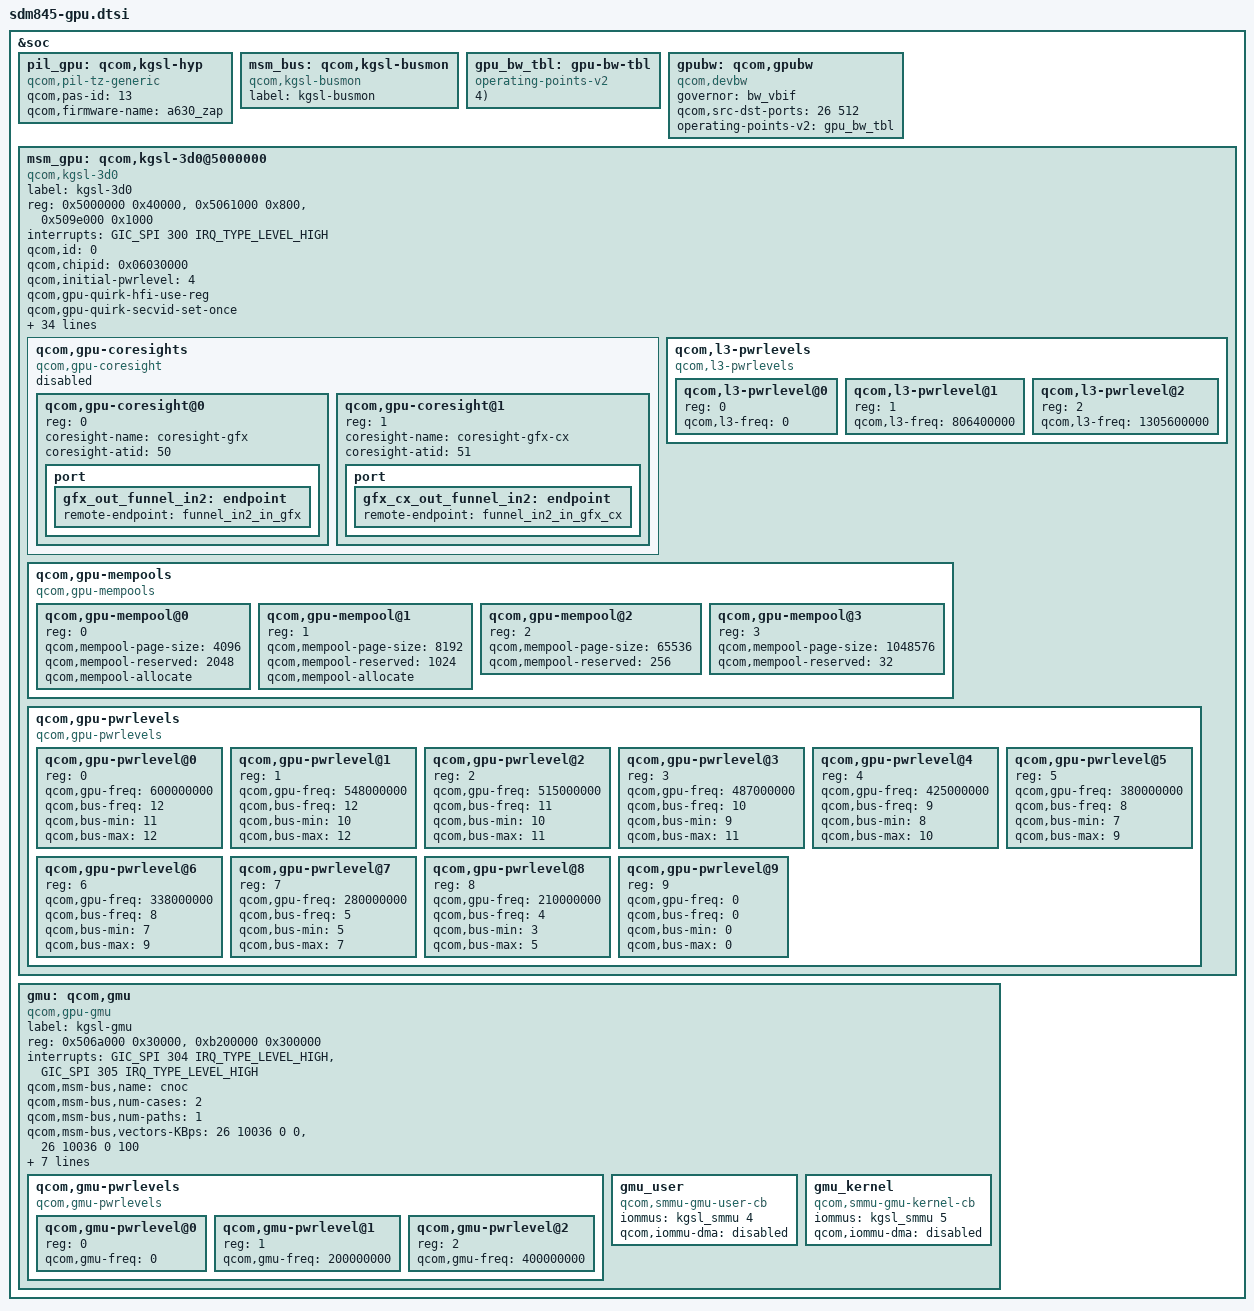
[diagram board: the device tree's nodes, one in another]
// SPDX-License-Identifier: GPL-2.0-only
/*
 * Copyright (c) 2017-2019, The Linux Foundation. All rights reserved.
 * GPU Optimized: Added intermediate freq levels, tuned defaults
 */

&soc {

	pil_gpu: qcom,kgsl-hyp {
		compatible = "qcom,pil-tz-generic";
		qcom,pas-id = <13>;
		qcom,firmware-name = "a630_zap";
	};

	msm_bus: qcom,kgsl-busmon{
		label = "kgsl-busmon";
		compatible = "qcom,kgsl-busmon";
	};

	gpu_bw_tbl: gpu-bw-tbl {
		compatible = "operating-points-v2";
		BW_OPP_ENTRY(   0, 4); /*    0 MB/s */
		BW_OPP_ENTRY( 100, 4); /*  381 MB/s */
		BW_OPP_ENTRY( 150, 4); /*  572 MB/s */
		BW_OPP_ENTRY( 200, 4); /*  762 MB/s */
		BW_OPP_ENTRY( 300, 4); /* 1144 MB/s */
		BW_OPP_ENTRY( 412, 4); /* 1571 MB/s */
		BW_OPP_ENTRY( 547, 4); /* 2086 MB/s */
		BW_OPP_ENTRY( 681, 4); /* 2597 MB/s */
		BW_OPP_ENTRY( 768, 4); /* 2929 MB/s */
		BW_OPP_ENTRY(1017, 4); /* 3879 MB/s */
		BW_OPP_ENTRY(1296, 4); /* 4943 MB/s */
		BW_OPP_ENTRY(1555, 4); /* 5931 MB/s */
		BW_OPP_ENTRY(1804, 4); /* 6881 MB/s */
	};

	gpubw: qcom,gpubw {
		compatible = "qcom,devbw";
		governor = "bw_vbif";
		qcom,src-dst-ports = <26 512>;
		operating-points-v2 = <&gpu_bw_tbl>;
	};

	msm_gpu: qcom,kgsl-3d0@5000000 {
		label = "kgsl-3d0";
		compatible = "qcom,kgsl-3d0", "qcom,kgsl-3d";
		status = "ok";
		reg = <0x5000000 0x40000>, <0x5061000 0x800>,
			<0x509e000 0x1000>;
		reg-names = "kgsl_3d0_reg_memory", "cx_dbgc",
			"cx_misc";
		interrupts = <GIC_SPI 300 IRQ_TYPE_LEVEL_HIGH>;
		interrupt-names = "kgsl_3d0_irq";
		qcom,id = <0>;

		qcom,chipid = <0x06030000>;

		qcom,initial-pwrlevel = <4>; /* Optimized: 338MHz (was 5=280MHz) */

		qcom,gpu-quirk-hfi-use-reg;
		qcom,gpu-quirk-secvid-set-once;

		qcom,idle-timeout = <60>; /* Optimized: 60ms (was 80ms) */
		qcom,no-nap;

		qcom,highest-bank-bit = <15>;

		qcom,min-access-length = <32>;

		qcom,ubwc-mode = <2>;

		qcom,snapshot-size = <1048576>;

		qcom,gpu-qdss-stm = <0x161c0000 0x40000>;

		qcom,tsens-name = "tsens_tz_sensor12";
		#cooling-cells = <2>;

		tzone-names = "gpu0-usr", "gpu1-usr";

		qcom,pm-qos-active-latency = <460>;

		clocks = <&clock_gfx GPU_CC_GX_GFX3D_CLK>,
			<&clock_gpucc GPU_CC_CXO_CLK>,
			<&clock_gcc GCC_DDRSS_GPU_AXI_CLK>,
			<&clock_gcc GCC_GPU_MEMNOC_GFX_CLK>,
			<&clock_gpucc GPU_CC_CX_GMU_CLK>,
			<&clock_cpucc L3_GPU_VOTE_CLK>;

		clock-names = "core_clk", "rbbmtimer_clk", "mem_clk",
				"mem_iface_clk", "gmu_clk", "l3_vote";

		qcom,isense-clk-on-level = <1>;

		qcom,gpubw-dev = <&gpubw>;
		qcom,bus-control;
		qcom,msm-bus,name = "grp3d";
		qcom,bus-width = <32>;
		qcom,msm-bus,num-cases = <13>;
		qcom,msm-bus,num-paths = <1>;
		qcom,msm-bus,vectors-KBps =
				<26 512 0 0>,
				<26 512 0 400000>,
				<26 512 0 600000>,
				<26 512 0 800000>,
				<26 512 0 1200000>,
				<26 512 0 1648000>,
				<26 512 0 2188000>,
				<26 512 0 2724000>,
				<26 512 0 3072000>,
				<26 512 0 4068000>,
				<26 512 0 5184000>,
				<26 512 0 6220000>,
				<26 512 0 7216000>;

		regulator-names = "vddcx", "vdd";
		vddcx-supply = <&gpu_cx_gdsc>;
		vdd-supply = <&gpu_gx_gdsc>;

		cache-slice-names = "gpu", "gpuhtw";

		qcom,gpu-coresights {
			#address-cells = <1>;
			#size-cells = <0>;
			compatible = "qcom,gpu-coresight";
			status = "disabled";
			qcom,gpu-coresight@0 {
				reg = <0>;
				coresight-name = "coresight-gfx";
				coresight-atid = <50>;
				port {
					gfx_out_funnel_in2: endpoint {
						remote-endpoint = <&funnel_in2_in_gfx>;
					};
				};
			};
			qcom,gpu-coresight@1 {
				reg = <1>;
				coresight-name = "coresight-gfx-cx";
				coresight-atid = <51>;
				port {
					gfx_cx_out_funnel_in2: endpoint {
						remote-endpoint = <&funnel_in2_in_gfx_cx>;
					};
				};
			};
		};

		qcom,l3-pwrlevels {
			#address-cells = <1>;
			#size-cells = <0>;
			compatible = "qcom,l3-pwrlevels";
			qcom,l3-pwrlevel@0 { reg = <0>; qcom,l3-freq = <0>; };
			qcom,l3-pwrlevel@1 { reg = <1>; qcom,l3-freq = <806400000>; };
			qcom,l3-pwrlevel@2 { reg = <2>; qcom,l3-freq = <1305600000>; };
		};

		qcom,gpu-mempools {
			#address-cells = <1>;
			#size-cells = <0>;
			compatible = "qcom,gpu-mempools";
			qcom,gpu-mempool@0 { reg = <0>; qcom,mempool-page-size = <4096>; qcom,mempool-reserved = <2048>; qcom,mempool-allocate; };
			qcom,gpu-mempool@1 { reg = <1>; qcom,mempool-page-size = <8192>; qcom,mempool-reserved = <1024>; qcom,mempool-allocate; };
			qcom,gpu-mempool@2 { reg = <2>; qcom,mempool-page-size = <65536>; qcom,mempool-reserved = <256>; };
			qcom,gpu-mempool@3 { reg = <3>; qcom,mempool-page-size = <1048576>; qcom,mempool-reserved = <32>; };
		};

		/* Optimized GPU Power Levels: 10 levels with intermediate freqs */
		qcom,gpu-pwrlevels {
			#address-cells = <1>;
			#size-cells = <0>;
			compatible = "qcom,gpu-pwrlevels";

			qcom,gpu-pwrlevel@0 {
				reg = <0>;
				qcom,gpu-freq = <600000000>;
				qcom,bus-freq = <12>;
				qcom,bus-min = <11>;
				qcom,bus-max = <12>;
			};

			qcom,gpu-pwrlevel@1 {
				reg = <1>;
				qcom,gpu-freq = <548000000>;
				qcom,bus-freq = <12>;
				qcom,bus-min = <10>;
				qcom,bus-max = <12>;
			};

			qcom,gpu-pwrlevel@2 {
				reg = <2>;
				qcom,gpu-freq = <515000000>; /* NEW: intermediate */
				qcom,bus-freq = <11>;
				qcom,bus-min = <10>;
				qcom,bus-max = <11>;
			};

			qcom,gpu-pwrlevel@3 {
				reg = <3>;
				qcom,gpu-freq = <487000000>;
				qcom,bus-freq = <10>;
				qcom,bus-min = <9>;
				qcom,bus-max = <11>;
			};

			qcom,gpu-pwrlevel@4 {
				reg = <4>;
				qcom,gpu-freq = <425000000>;
				qcom,bus-freq = <9>;
				qcom,bus-min = <8>;
				qcom,bus-max = <10>;
			};

			qcom,gpu-pwrlevel@5 {
				reg = <5>;
				qcom,gpu-freq = <380000000>; /* NEW: intermediate */
				qcom,bus-freq = <8>;
				qcom,bus-min = <7>;
				qcom,bus-max = <9>;
			};

			qcom,gpu-pwrlevel@6 {
				reg = <6>;
				qcom,gpu-freq = <338000000>;
				qcom,bus-freq = <8>;
				qcom,bus-min = <7>;
				qcom,bus-max = <9>;
			};

			qcom,gpu-pwrlevel@7 {
				reg = <7>;
				qcom,gpu-freq = <280000000>;
				qcom,bus-freq = <5>;
				qcom,bus-min = <5>;
				qcom,bus-max = <7>;
			};

			qcom,gpu-pwrlevel@8 {
				reg = <8>;
				qcom,gpu-freq = <210000000>;
				qcom,bus-freq = <4>;
				qcom,bus-min = <3>;
				qcom,bus-max = <5>;
			};

			qcom,gpu-pwrlevel@9 {
				reg = <9>;
				qcom,gpu-freq = <0>;
				qcom,bus-freq = <0>;
				qcom,bus-min = <0>;
				qcom,bus-max = <0>;
			};
		};
	};

	gmu: qcom,gmu {
		label = "kgsl-gmu";
		compatible = "qcom,gpu-gmu";

		reg = <0x506a000 0x30000>, <0xb200000 0x300000>;
		reg-names = "kgsl_gmu_reg", "kgsl_gmu_pdc_reg";

		interrupts = <GIC_SPI 304 IRQ_TYPE_LEVEL_HIGH>,
			     <GIC_SPI 305 IRQ_TYPE_LEVEL_HIGH>;
		interrupt-names = "kgsl_hfi_irq", "kgsl_gmu_irq";

		qcom,msm-bus,name = "cnoc";
		qcom,msm-bus,num-cases = <2>;
		qcom,msm-bus,num-paths = <1>;
		qcom,msm-bus,vectors-KBps =
			<26 10036 0 0>,
			<26 10036 0 100>;

		regulator-names = "vddcx", "vdd";
		vddcx-supply = <&gpu_cx_gdsc>;
		vdd-supply = <&gpu_gx_gdsc>;

		clocks = <&clock_gpucc GPU_CC_CX_GMU_CLK>,
			 <&clock_gpucc GPU_CC_CXO_CLK>,
			 <&clock_gcc GCC_DDRSS_GPU_AXI_CLK>,
			 <&clock_gcc GCC_GPU_MEMNOC_GFX_CLK>;

		clock-names = "gmu_clk", "cxo_clk", "axi_clk",
			      "memnoc_clk";

		qcom,gmu-pwrlevels {
			#address-cells = <1>;
			#size-cells = <0>;
			compatible = "qcom,gmu-pwrlevels";

			qcom,gmu-pwrlevel@0 {
				reg = <0>;
				qcom,gmu-freq = <0>;
			};

			qcom,gmu-pwrlevel@1 {
				reg = <1>;
				qcom,gmu-freq = <200000000>;
			};

			qcom,gmu-pwrlevel@2 {
				reg = <2>;
				qcom,gmu-freq = <400000000>;
			};
		};

		gmu_user: gmu_user {
			compatible = "qcom,smmu-gmu-user-cb";
			iommus = <&kgsl_smmu 4>;
			qcom,iommu-dma = "disabled";
		};

		gmu_kernel: gmu_kernel {
			compatible = "qcom,smmu-gmu-kernel-cb";
			iommus = <&kgsl_smmu 5>;
			qcom,iommu-dma = "disabled";
		};
	};
};
